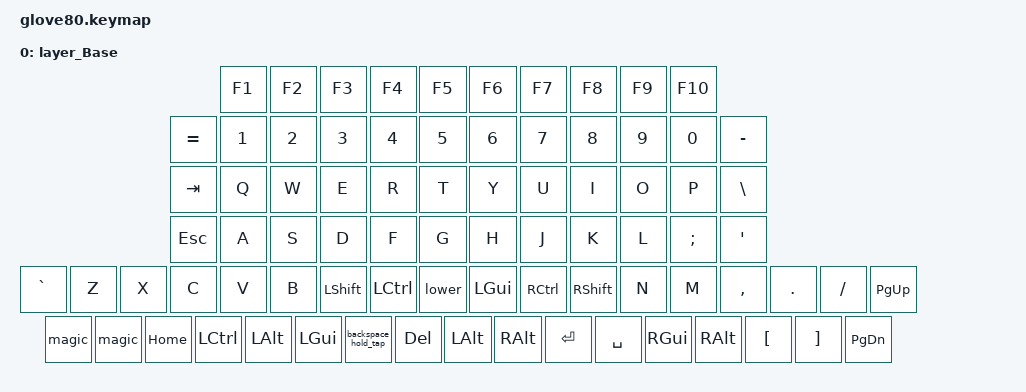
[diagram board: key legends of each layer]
/*
 * Copyright (c) 2020 The ZMK Contributors
 * Copyright (c) 2023 Innaworks Development Limited, trading as MoErgo
 *
 * SPDX-License-Identifier: MIT
 */

/* THIS FILE WAS GENERATED BY GLOVE80 LAYOUT EDITOR
 *
 * This file was generated automatically. You may or may not want to
 * edit it directly.
 */

#include <behaviors.dtsi>
/* Include all behavior includes needed */
#include <dt-bindings/zmk/outputs.h>
#include <dt-bindings/zmk/keys.h>
#include <dt-bindings/zmk/bt.h>
#include <dt-bindings/zmk/rgb.h>

/* Automatically generated layer name #define */
#define LAYER_Base 0
#define LAYER_Lower 1
#define LAYER_Magic 2

/* To deal with the situation where there is no Lower layer, to keep &lower happy */
#ifndef LAYER_Lower
#define LAYER_Lower 0
#endif

/* Custom Device-tree */

/* Glove80 system behavior & macros */
 / {
    behaviors {
        // Existing "lower" tap dance behavior
        lower: lower {
            compatible = "zmk,behavior-tap-dance";
            #binding-cells = <0>;
            tapping-term-ms = <200>;
            bindings = <&mo LAYER_Lower> <&to LAYER_Lower>;
        };

        // Existing "magic" hold-tap behavior
        magic: magic {
            compatible = "zmk,behavior-hold-tap";
            #binding-cells = <2>;
            flavor = "tap-preferred";
            tapping-term-ms = <200>;
            bindings = <&mo> <&rgb_ug_status_macro>;
        };

        // New Hold-Tap behavior for Backspace
        backspace_hold_tap: backspace_hold_tap {
            compatible = "zmk,behavior-hold-tap";
            #binding-cells = <2>;
            tapping-term-ms = <200>; // Adjust if needed
            bindings = <&kp BSPC> <&ctrl_shift>;
        };

        // New behavior-mod-hold for CTRL_SHIFT
        ctrl_shift: ctrl_shift {
            compatible = "zmk,behavior-mod-hold";
            #binding-cells = <1>;
            mods = <0x00000003>; // MOD_LCTRL | MOD_LSHIFT
        };
    };

    macros {
        // Existing RGB UnderGlow Status Macro
        rgb_ug_status_macro: rgb_ug_status_macro {
            compatible = "zmk,behavior-macro";
            #binding-cells = <0>;
            bindings = <&rgb_ug RGB_STATUS>;
        };

        // Existing BT_Select Macros
        bt_select_0: bt_select_0 {
            compatible = "zmk,behavior-macro";
            #binding-cells = <0>;
            bindings = <&out OUT_BLE> <&bt BT_SEL 0>;
        };
        bt_select_1: bt_select_1 {
            compatible = "zmk,behavior-macro";
            #binding-cells = <0>;
            bindings = <&out OUT_BLE> <&bt BT_SEL 1>;
        };
        bt_select_2: bt_select_2 {
            compatible = "zmk,behavior-macro";
            #binding-cells = <0>;
            bindings = <&out OUT_BLE> <&bt BT_SEL 2>;
        };
        bt_select_3: bt_select_3 {
            compatible = "zmk,behavior-macro";
            #binding-cells = <0>;
            bindings = <&out OUT_BLE> <&bt BT_SEL 3>;
        };
    };

    combos {
        compatible = "zmk,combos";
    };
};

/* Automatically generated macro definitions */
 / {
    macros {
        // Any other macros can be defined here
    };
};

/* Automatically generated behavior definitions */
 / {
    behaviors {
        // Any other behaviors can be defined here
    };
};

/* Automatically generated combos definitions */
 / {
    combos {
        compatible = "zmk,combos";
    };
};

/* Automatically generated keymap */
 / {
    keymap {
        compatible = "zmk,keymap";


        layer_Base {
            bindings = <
               &kp F1    &kp F2     &kp F3    &kp F4    &kp F5                                                                                    &kp F6     &kp F7    &kp F8    &kp F9    &kp F10
            &kp EQUAL    &kp N1     &kp N2    &kp N3    &kp N4  &kp N5                                                                  &kp N6    &kp N7     &kp N8    &kp N9    &kp N0  &kp MINUS
              &kp TAB     &kp Q      &kp W     &kp E     &kp R   &kp T                                                                   &kp Y     &kp U      &kp I     &kp O     &kp P   &kp BSLH
              &kp ESC     &kp A      &kp S     &kp D     &kp F   &kp G                                                                   &kp H     &kp J      &kp K     &kp L  &kp SEMI    &kp SQT
            &kp GRAVE     &kp Z      &kp X     &kp C     &kp V   &kp B  &kp LSHFT  &kp LCTRL    &lower  &kp LGUI  &kp RCTRL  &kp RSHFT   &kp N     &kp M  &kp COMMA   &kp DOT  &kp FSLH  &kp PG_UP
         &magic &magic &kp HOME  &kp LCTRL  &kp LALT  &kp LGUI           &backspace_hold_tap    &kp DEL  &kp LALT  &kp RALT    &kp RET  &kp SPACE          &kp RGUI   &kp RALT  &kp LBKT  &kp RBKT  &kp PG_DN
            >;
        };

    };
};
